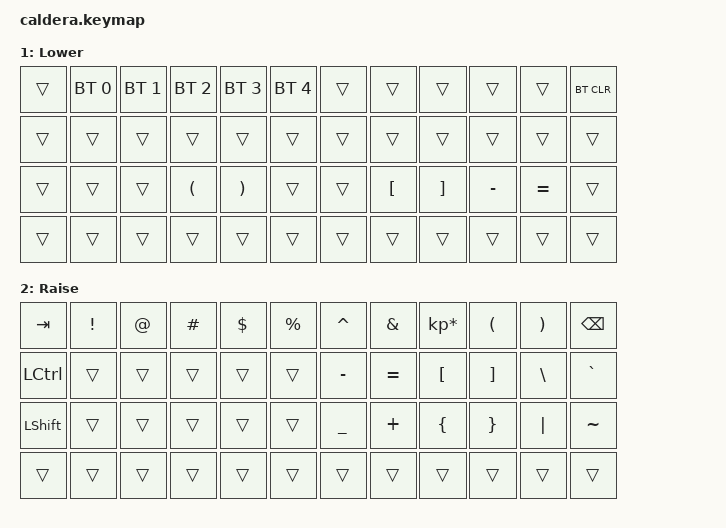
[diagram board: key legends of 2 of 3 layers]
#include <behaviors.dtsi>
#include <dt-bindings/zmk/keys.h>
#include <dt-bindings/zmk/bt.h>

/ {
        keymap {
                compatible = "zmk,keymap";

                default_layer {
// ---------------------------------------------------------------------------------
// |   `  |  1  |  2  |  3  |  4  |  5  |     |  6  |  7  |  8  |  9  |  0  | BKSP |
// | TAB  |  Q  |  W  |  E  |  R  |  T  |     |  Y  |  U  |  I  |  O  |  P  |  \   |
// | RSE  |  A  |  S  |  D  |  F  |  G  |     |  H  |  J  |  K  |  L  |  ;  |  ENT |
// | SHFT |  Z  |  X  |  C  |  V  |  B  |     |  N  |  M  |  ,  |  .  |  /  | APOS |
// | CTRL | ALT | GUI | SPC | SPC | SPC |     | SPC | LOW |LARW |DARW |UARW | RARW |
                        display-name = "Base";
                        bindings = <
   &kp GRAVE  &kp N1    &kp N2    &kp N3     &kp N4     &kp N5               &kp N6     &kp N7  &kp N8     &kp N9    &kp N0    &kp BSPC
   &kp TAB    &kp Q     &kp W     &kp E      &kp R      &kp T                &kp Y      &kp U   &kp I      &kp O     &kp P     &kp BSLH
   &mo 2      &kp A     &kp S     &kp D      &kp F      &kp G                &kp H      &kp J   &kp K      &kp L     &kp SEMI  &kp RET
   &kp LSHFT  &kp Z     &kp X     &kp C      &kp V      &kp B                &kp N      &kp M   &kp COMMA  &kp DOT   &kp FSLH  &kp APOS
   &kp LCTRL  &kp LALT  &kp LGUI  &kp SPACE  &kp LALT   &kp LGUI             &kp SPACE  &mo 1   &kp LARW   &kp DARW  &kp UARW  &kp RARW
                        >;
                };
                lower_layer {
// -----------------------------------------------------------------------------
// |   | BT1 | BT2 |  BT3 |  BT4 | BT5 |     |   |      |      |   |   | BTCLR |
// |   |     |     |      |      |     |     |   |      |      |   |   |       |
// |   |     |     | LPAR | RPAR |     |     |   | LBKT | RBKT |   |   |       |
// |   |     |     |      |      |     |     |   |      |      |   |   |       |
                        display-name = "Lower";
                        bindings = <
   &trans    &bt BT_SEL 0   &bt BT_SEL 1   &bt BT_SEL 2   &bt BT_SEL 3   &bt BT_SEL 4      &trans    &trans    &trans    &trans     &trans     &bt BT_CLR
   &trans    &trans         &trans         &trans         &trans         &trans            &trans    &trans    &trans    &trans     &trans     &trans
   &trans    &trans         &trans         &kp LPAR       &kp RPAR       &trans            &trans    &kp LBKT  &kp RBKT  &kp MINUS  &kp EQUAL  &trans
   &trans    &trans         &trans         &trans         &trans         &trans            &trans    &trans    &trans    &trans     &trans     &trans
                        >;
                };

                raise_layer {
// -------------------------------------------------------------------------------
// |  TAB |  !  |  @  |  #  |  $  |  %  |   |  ^  |  &  |  *  |  (  |  )  | BKSP |
// | CTRL |     |     |     |     |     |   |  -  |  =  |  [  |  ]  |  \  |  `   |
// | SHFT |     |     |     |     |     |   |  _  |  +  |  {  |  }  | "|" |  ~   |
// |      |     |     |     |     |     |   |     |     |     |     |     |      |
                        display-name = "Raise";
                        bindings = <
   &kp TAB     &kp EXCL   &kp AT   &kp HASH   &kp DLLR   &kp PRCNT   &kp CARET    &kp AMPS     &kp KP_MULTIPLY   &kp LPAR    &kp RPAR    &kp BSPC
   &kp LCTRL   &trans     &trans   &trans     &trans     &trans      &kp MINUS    &kp EQUAL    &kp LBKT          &kp RBKT    &kp BSLH    &kp GRAVE
   &kp LSHFT   &trans     &trans   &trans     &trans     &trans      &kp UNDER    &kp PLUS     &kp LBRC          &kp RBRC    &kp PIPE    &kp TILDE
   &trans      &trans     &trans   &trans     &trans     &trans      &trans       &trans       &trans            &trans      &trans      &trans 
                        >;
                };

                extra_1 {
                        status = "reserved";
                };

                extra_2 {
                        status = "reserved";
                };

                extra_3 {
                        status = "reserved";
                };
        };
};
